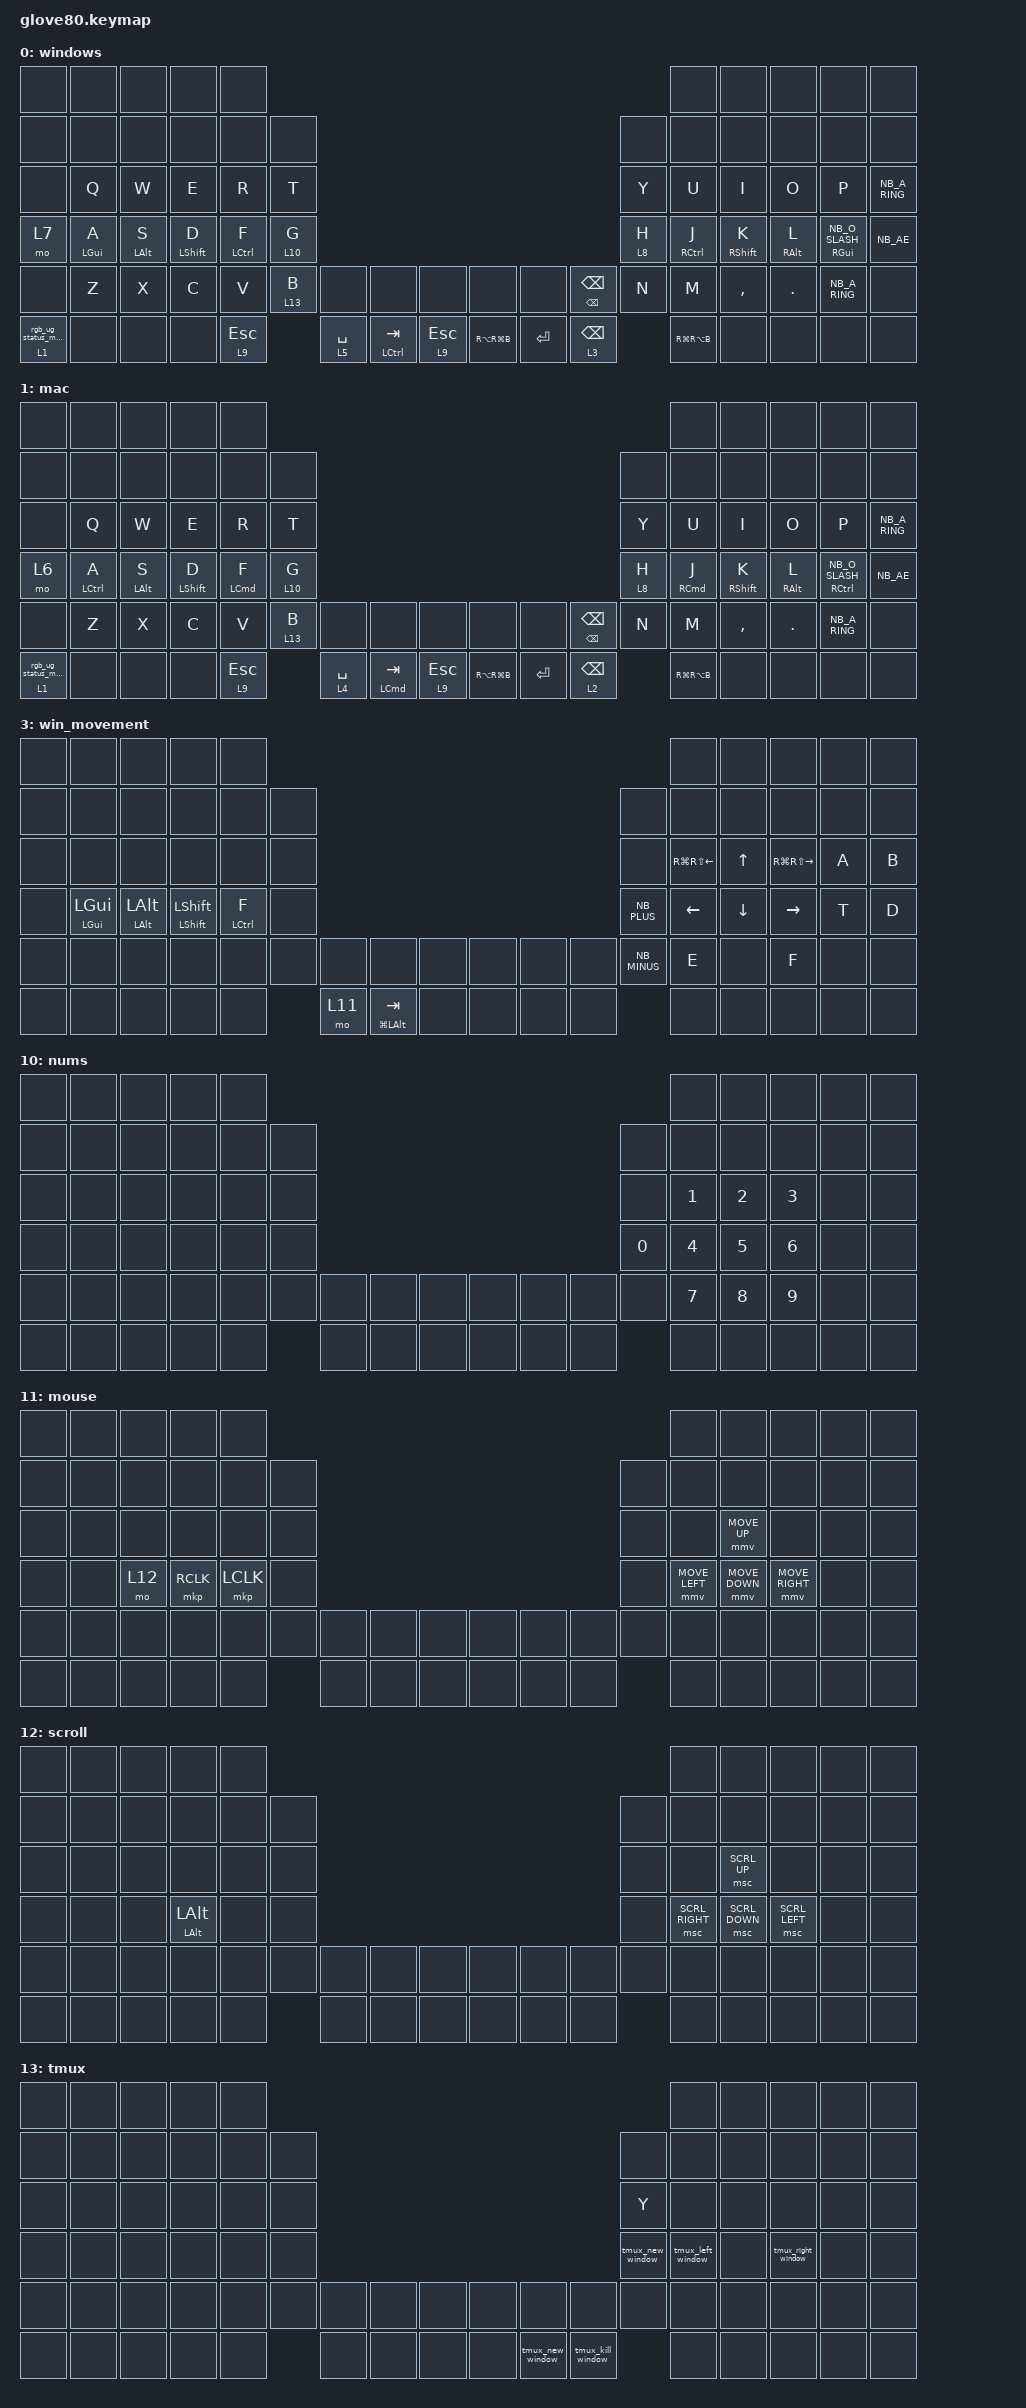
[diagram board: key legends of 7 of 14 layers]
/*
 * Copyright (c) 2020 The ZMK Contributors
 *
 * SPDX-License-Identifier: MIT
 */

#include "keys_nb.h"
#include <behaviors.dtsi>
#include <dt-bindings/zmk/bt.h>
#include <dt-bindings/zmk/keys.h>
#include <dt-bindings/zmk/outputs.h>
#include <dt-bindings/zmk/pointing.h>
#include <dt-bindings/zmk/rgb.h>

#define HYPER LC(LS(LG(LALT)))
#define ZMK_POINTING_DEFAULT_MOVE_VAL 900

// layers

#define DEFAULT 0
#define LOWER 1
#define MAGIC 2
#define FACTORY_TEST 3

/ {
    behaviors {
        // For the "layer" key, it'd nice to be able to use it as either a shift or a toggle.
        // Configure it as a tap dance, so the first tap (or hold) is a &mo and the second tap is a &to

        magic: magic_hold_tap {
            compatible = "zmk,behavior-hold-tap";
            label = "MAGIC_HOLD_TAP";
            #binding-cells = <2>;
            flavor = "tap-preferred";
            tapping-term-ms = <200>;
            bindings = <&mo>, <&rgb_ug_status_macro>;
        };

        mt: mod_tap {
            compatible = "zmk,behavior-hold-tap";
            bindings = <&kp>, <&kp>;

            #binding-cells = <2>;
            tapping-term-ms = <200>;
            require-prior-idle-ms = <150>;
            flavor = "tap-preferred";
            hold-trigger-on-release;
        };
    };

    macros {
        rgb_ug_status_macro: rgb_ug_status_macro_0 {
            label = "RGB_UG_STATUS";
            compatible = "zmk,behavior-macro";
            #binding-cells = <0>;
            bindings = <&rgb_ug RGB_STATUS>;
        };

        bt_0: bt_profile_macro_0 {
            label = "BT_0";
            compatible = "zmk,behavior-macro";
            #binding-cells = <0>;
            bindings = <&out OUT_BLE &bt BT_SEL 0>;
        };

        bt_1: bt_profile_macro_1 {
            label = "BT_1";
            compatible = "zmk,behavior-macro";
            #binding-cells = <0>;
            bindings = <&out OUT_BLE &bt BT_SEL 1>;
        };

        bt_2: bt_profile_macro_2 {
            label = "BT_2";
            compatible = "zmk,behavior-macro";
            #binding-cells = <0>;
            bindings = <&out OUT_BLE &bt BT_SEL 2>;
        };

        bt_3: bt_profile_macro_3 {
            label = "BT_3";
            compatible = "zmk,behavior-macro";
            #binding-cells = <0>;
            bindings = <&out OUT_BLE &bt BT_SEL 3>;
        };

        tmux_new_window: tmux_new_window {
            label = "TMUX_NEW_WINDOW";
            compatible = "zmk,behavior-macro";
            #binding-cells = <0>;
            bindings = <&kp RC(B) &kp C>;
        };

        tmux_kill_window: tmux_kill_window {
            label = "TMUX_KILL_WINDOW";
            compatible = "zmk,behavior-macro";
            #binding-cells = <0>;
            bindings = <&kp RC(B) &kp NB_AMPERSAND>;
        };

        tmux_left_window: tmux_left_arrow {
            label = "TMUX_LEFT_ARROW";
            compatible = "zmk,behavior-macro";
            #binding-cells = <0>;
            bindings = <&kp RC(B) &kp P>;
        };

        tmux_right_window: tmux_right_arrow {
            label = "TMUX_RIGHT_ARROW";
            compatible = "zmk,behavior-macro";
            #binding-cells = <0>;
            bindings = <&kp RC(B) &kp N>;
        };

        os_mac: os_mac {
            compatible = "zmk,behavior-macro";
            #binding-cells = <0>;
            bindings = <&bt BT_SEL 0 &to 1>;
            label = "OS_MAC";
        };

        os_win: os_win {
            compatible = "zmk,behavior-macro";
            #binding-cells = <0>;
            bindings = <&bt BT_SEL 1 &to 0>;
            label = "OS_WIN";
        };

        qurly_left: qurly_left {
            compatible = "zmk,behavior-macro";
            #binding-cells = <0>;
            bindings = <&kp RA(N7)>;
            label = "QURLY_LEFT";
        };

        os_mac2: os_mac2 {
            compatible = "zmk,behavior-macro";
            #binding-cells = <0>;
            bindings = <&bt BT_SEL 2 &to 1>;
            label = "OS_MAC2";
        };
    };

    keymap {
        compatible = "zmk,keymap";

        windows_base {
            label = "windows";
            bindings = <
&none       &none           &none           &none             &none                                                                                                                                 &none                &none              &none            &none                     &none
&none       &none           &none           &none             &none               &none                                                                                                    &none    &none                &none              &none            &none                     &none
&none       &kp Q           &kp W           &kp E             &kp R               &kp T                                                                                                    &kp Y    &kp U                &kp I              &kp O            &kp P                     &kp NB_A_RING
&mo 7       &mt LEFT_GUI A  &mt LEFT_ALT S  &mt LEFT_SHIFT D  &mt LEFT_CONTROL F  &lt 10 G                                                                                                 &lt 8 H  &mt RIGHT_CONTROL J  &mt RIGHT_SHIFT K  &mt RIGHT_ALT L  &mt RIGHT_GUI NB_O_SLASH  &kp NB_AE
&none       &kp Z           &kp X           &kp C             &kp V               &lt 13 B  &none        &none                 &none      &none          &none    &mt BACKSPACE BACKSPACE  &kp N    &kp M                &kp COMMA          &kp DOT          &kp NB_A_RING             &none
&magic 1 0  &none           &none           &none             &lt 9 ESC                     &lt 5 SPACE  &mt LEFT_CONTROL TAB  &lt 9 ESC  &kp RA(RG(B))  &kp RET  &lt 3 BACKSPACE                   &kp RG(RA(B))        &none              &none            &none                     &none
            >;
        };

        mac_base {
            // ---------------------------------------------------------------------------------------------------------------------------------
            // |  F1   |  F2 |  F3 |  F4  |  F5  |                                                               |  F6   |  F7   |  F8  |   F9  |  F10 |
            // |  =    |  1  |  2  |  3   |  4   |  5   |                                                 |  6   |   7   |   8   |  9   |   0   |   -  |
            // |  TAB  |  Q  |  W  |  E   |  R   |  T   |                                                 |  Y   |   U   |   I   |  O   |   P   |   \  |
            // |  ESC  |  A  |  S  |  D   |  F   |  G   |                                                 |  H   |   J   |   K   |  L   |   ;   |   '  |
            // |   `   |  Z  |  X  |  C   |  V   |  B   | LSHFT | LCTRL | LOWER | | LGUI  | RCTRL | RSHFT |  N   |   M   |   ,   |  .   |   /   | PGUP |
            // | MAGIC | HOME| END | LEFT | RIGHT|      | BSPC  | DEL   | LALT  | | RALT  | RET   | SPACE |      |  UP   | DOWN  |  [   |   ]   | PGDN |

            bindings = <
&none       &none               &none           &none             &none                                                                                                                                 &none                &none              &none            &none                         &none
&none       &none               &none           &none             &none               &none                                                                                                    &none    &none                &none              &none            &none                         &none
&none       &kp Q               &kp W           &kp E             &kp R               &kp T                                                                                                    &kp Y    &kp U                &kp I              &kp O            &kp P                         &kp NB_A_RING
&mo 6       &mt LEFT_CONTROL A  &mt LEFT_ALT S  &mt LEFT_SHIFT D  &mt LEFT_COMMAND F  &lt 10 G                                                                                                 &lt 8 H  &mt RIGHT_COMMAND J  &mt RIGHT_SHIFT K  &mt RIGHT_ALT L  &mt RIGHT_CONTROL NB_O_SLASH  &kp NB_AE
&none       &kp Z               &kp X           &kp C             &kp V               &lt 13 B  &none        &none                 &none      &none          &none    &mt BACKSPACE BACKSPACE  &kp N    &kp M                &kp COMMA          &kp DOT          &kp NB_A_RING                 &none
&magic 1 0  &none               &none           &none             &lt 9 ESC                     &lt 4 SPACE  &mt LEFT_COMMAND TAB  &lt 9 ESC  &kp RA(RG(B))  &kp RET  &lt 2 BACKSPACE                   &kp RG(RA(B))        &none              &none            &none                         &none
            >;

            label = "mac";
        };

        Mac_Movement {
            bindings = <
&none  &none                          &none                  &none                      &none                                                                                                                                          &none           &none           &none            &none  &none
&none  &none                          &none                  &none                      &none                          &none                                                                                             &none         &none           &none           &none            &none  &none
&none  &none                          &none                  &none                      &none                          &none                                                                                             &none         &kp HOME        &kp UP_ARROW    &kp END          &kp A  &kp B
&none  &mt LEFT_CONTROL LEFT_CONTROL  &mt LEFT_ALT LEFT_ALT  &mt LEFT_SHIFT LEFT_SHIFT  &mt LEFT_COMMAND LEFT_COMMAND  &none                                                                                             &kp NB_PLUS   &kp LEFT_ARROW  &kp DOWN_ARROW  &kp RIGHT_ARROW  &kp T  &kp D
&none  &none                          &none                  &none                      &none                          &none  &kp LS(LC(LG(LEFT_ALT)))  &none                     &none             &none  &none  &none  &kp NB_MINUS  &kp E           &none           &kp F            &none  &none
&none  &none                          &none                  &none                      &none                                 &mo 11                    &kp LG(LC(LS(LEFT_ALT)))  &kp LEFT_CONTROL  &none  &none  &none                &none           &none           &none            &none  &none
            >;

            label = "mac_movement";
        };

        Windows_Movement {
            label = "win_movement";
            bindings = <
&none  &none                  &none                  &none                      &none                                                                                              &none                   &none           &none                    &none  &none
&none  &none                  &none                  &none                      &none               &none                                                            &none         &none                   &none           &none                    &none  &none
&none  &none                  &none                  &none                      &none               &none                                                            &none         &kp RG(RS(LEFT_ARROW))  &kp UP_ARROW    &kp RG(RS(RIGHT_ARROW))  &kp A  &kp B
&none  &mt LEFT_GUI LEFT_GUI  &mt LEFT_ALT LEFT_ALT  &mt LEFT_SHIFT LEFT_SHIFT  &mt LEFT_CONTROL F  &none                                                            &kp NB_PLUS   &kp LEFT_ARROW          &kp DOWN_ARROW  &kp RIGHT_ARROW          &kp T  &kp D
&none  &none                  &none                  &none                      &none               &none  &none   &none                 &none  &none  &none  &none  &kp NB_MINUS  &kp E                   &none           &kp F                    &none  &none
&none  &none                  &none                  &none                      &none                      &mo 11  &mt LG(LEFT_ALT) TAB  &none  &none  &none  &none                &none                   &none           &none                    &none  &none
            >;
        };

        mac_symbols {
            bindings = <
&none  &none                                  &none                    &none                &none                                                                                                      &none                    &none                     &none         &none                 &none
&none  &none                                  &none                    &none                &none              &none                                                               &none               &none                    &none                     &none         &none                 &none
&none  &kp LS(NUMBER_4)                       &kp NB_LESS_THAN         &kp NB_GREATER_THAN  &kp NB_UNDERSCORE  &kp LA(N7)                                                          &kp NB_AMPERSAND    &kp RS(RA(NB_N8))        &kp RS(RA(NB_N9))         &kp NB_EQUAL  &kp RA(SINGLE_QUOTE)  &none
&none  &kp NB_DOUBLE_QUOTES                   &kp LA(NB_SINGLE_QUOTE)  &kp NB_SEMICOLON     &kp NB_COLON       &kp NB_SLASH                                                        &kp NB_QUESTION     &kp NB_LEFT_PARENTHESIS  &kp NB_RIGHT_PARENTHESIS  &kp NB_PLUS   &kp NB_SQT            &none
&none  &mt LA(LC(LG(LEFT_SHIFT))) LEFT_SHIFT  &none                    &none                &kp NB_HASH        &kp NB_ASTERISK  &none  &none  &none  &none  &none           &none  &kp NB_EXCLAMATION  &kp NB_LEFT_BRACKET      &kp NB_RIGHT_BRACKET      &kp NB_MINUS  &none                 &none
&none  &none                                  &none                    &none                &none                               &none  &none  &none  &none  &kp NB_PERCENT  &none                      &none                    &none                     &none         &none                 &none
            >;

            label = "m_symbols";
        };

        win_symbols {
            label = "w_symbols";
            bindings = <
&none  &none                                  &none             &none                &none                                                                                                      &none                    &none                              &none         &none            &none
&none  &none                                  &none             &none                &none              &none                                                               &none               &none                    &none                              &none         &none            &none
&none  &kp DLLR                               &kp NB_LESS_THAN  &kp NB_GREATER_THAN  &kp NB_UNDERSCORE  &kp NB_PIPE                                                         &kp NB_AMPERSAND    &kp NB_LEFT_BRACE        &mt NB_RIGHT_BRACE NB_RIGHT_BRACE  &kp NB_EQUAL  &kp NB_EQUAL     &none
&none  &kp NB_DOUBLE_QUOTES                   &kp NB_SQT        &kp NB_SEMICOLON     &kp NB_COLON       &kp NB_SLASH                                                        &kp NB_QUESTION     &kp NB_LEFT_PARENTHESIS  &kp NB_RIGHT_PARENTHESIS           &kp NB_PLUS   &mt NB_AT NB_AT  &none
&none  &mt LA(LC(LG(LEFT_SHIFT))) LEFT_SHIFT  &kp NB_BACKSLASH  &none                &kp NB_HASH        &kp NB_ASTERISK  &none  &none  &none  &none  &none           &none  &kp NB_EXCLAMATION  &kp RC(RA(N8))           &kp RC(RA(N9))                     &kp NB_MINUS  &none            &none
&none  &none                                  &none             &none                &none                               &none  &none  &none  &none  &kp NB_PERCENT  &none                      &none                    &none                              &none         &none            &none
            >;
        };

        Misc_mac {
            bindings = <
&none  &none  &none       &none                 &none                                                                                                &none              &none            &none       &none       &none
&none  &none  &none       &none                 &none                 &none                                                        &none             &none              &none            &none       &none       &none
&none  &none  &bt BT_CLR  &none                 &os_mac               &os_win                                                      &kp C_PLAY_PAUSE  &kp C_VOLUME_DOWN  &kp C_VOLUME_UP  &kp C_PREV  &kp C_NEXT  &none
&none  &none  &none       &kp LS(LG(NUMBER_5))  &kp LS(LG(NUMBER_4))  &kp LS(LA(S))                                                &none             &none              &none            &none       &none       &none
&none  &none  &none       &none                 &none                 &kp LS(LA(LC(S)))  &none  &none  &none  &none  &none  &none  &none             &none              &none            &none       &none       &none
&none  &none  &none       &none                 &none                                    &none  &none  &none  &none  &none  &none                    &none              &none            &none       &none       &none
            >;

            label = "misc_mac";
        };

        misc_win {
            label = "misc_win";
            bindings = <
&none  &none  &none       &none                 &none                                                                                         &none              &none            &none       &none       &none
&none  &none  &none       &none                 &none          &none                                                        &none             &none              &none            &none       &none       &none
&none  &none  &bt BT_CLR  &none                 &os_mac        &os_win                                                      &kp C_PLAY_PAUSE  &kp C_VOLUME_DOWN  &kp C_VOLUME_UP  &kp C_PREV  &kp C_NEXT  &none
&none  &none  &none       &kp LS(LG(NUMBER_5))  &kp LS(LG(S))  &kp LS(LA(S))                                                &none             &kp RA(RS(N5))     &none            &none       &none       &none
&none  &none  &none       &none                 &none          &kp LS(LA(LC(S)))  &none  &none  &none  &none  &none  &none  &none             &none              &none            &none       &none       &none
&none  &none  &none       &none                 &none                             &none  &none  &none  &none  &none  &none                    &none              &none            &none       &none       &none
            >;
        };

        Apps {
            bindings = <
&none                   &none       &none           &none       &none                                                                          &none  &none  &none  &none  &none
&none                   &none       &none           &none       &none       &none                                                       &none  &none  &none  &none  &none  &none
&kp LS(LA(LC(LG(N1))))  &kp LC(N8)  &kp LC(N1)      &kp LC(N2)  &kp LC(N3)  &kp LC(NUMBER_0)                                            &none  &none  &none  &none  &none  &none
&none                   &kp LC(N9)  &kp LS(LC(N7))  &kp LC(N7)  &kp LC(N6)  &kp LS(LC(N6))                                              &none  &none  &none  &none  &none  &none
&none                   &none       &none           &none       &none       &kp LG(Q)         &none  &none  &none  &none  &none  &none  &none  &none  &none  &none  &none  &none
&none                   &none       &none           &none       &none                         &none  &none  &none  &none  &none  &none         &none  &none  &none  &none  &none
            >;

            label = "apps";
        };

        IDE {
            bindings = <
&none  &none  &none  &none  &none                                                                                &none                         &none             &none                         &none  &none
&none  &none  &none  &none  &none  &none                                                              &none      &none                         &none             &none                         &none  &none
&none  &none  &none  &none  &none  &none                                                              &kp RG(W)  &kp RG(NUMBER_1)              &kp RG(NUMBER_2)  &kp RG(NUMBER_3)              &none  &none
&none  &none  &none  &none  &none  &none                                                              &kp RG(P)  &kp RG(RC(RA(RS(NUMBER_5))))  &none             &kp RS(RA(RC(RG(NUMBER_6))))  &none  &none
&none  &none  &none  &none  &none  &none  &none  &none  &none  &none  &none            &none          &none      &none                         &none             &none                         &none  &none
&none  &none  &none  &none  &none         &none  &none  &none  &none  &kp RC(NB_PLUS)  &kp RG(RS(E))             &none                         &none             &none                         &none  &none
            >;

            label = "ide";
        };

        Nums {
            bindings = <
&none  &none  &none  &none  &none                                                           &none         &none   &none   &none  &none
&none  &none  &none  &none  &none  &none                                            &none   &none         &none   &none   &none  &none
&none  &none  &none  &none  &none  &none                                            &none   &kp N1        &kp N2  &kp N3  &none  &none
&none  &none  &none  &none  &none  &none                                            &kp N0  &kp NUMBER_4  &kp N5  &kp N6  &none  &none
&none  &none  &none  &none  &none  &none  &none  &none  &none  &none  &none  &none  &none   &kp N7        &kp N8  &kp N9  &none  &none
&none  &none  &none  &none  &none         &none  &none  &none  &none  &none  &none          &none         &none   &none   &none  &none
            >;

            label = "nums";
        };

        Mouse {
            bindings = <
&none  &none  &none   &none      &none                                                              &none           &none           &none            &none  &none
&none  &none  &none   &none      &none      &none                                            &none  &none           &none           &none            &none  &none
&none  &none  &none   &none      &none      &none                                            &none  &none           &mmv MOVE_UP    &none            &none  &none
&none  &none  &mo 12  &mkp RCLK  &mkp LCLK  &none                                            &none  &mmv MOVE_LEFT  &mmv MOVE_DOWN  &mmv MOVE_RIGHT  &none  &none
&none  &none  &none   &none      &none      &none  &none  &none  &none  &none  &none  &none  &none  &none           &none           &none            &none  &none
&none  &none  &none   &none      &none             &none  &none  &none  &none  &none  &none         &none           &none           &none            &none  &none
            >;

            label = "mouse";
        };

        Scroll {
            bindings = <
&none  &none  &none  &none                  &none                                                          &none            &none           &none           &none  &none
&none  &none  &none  &none                  &none  &none                                            &none  &none            &none           &none           &none  &none
&none  &none  &none  &none                  &none  &none                                            &none  &none            &msc SCRL_UP    &none           &none  &none
&none  &none  &none  &mt LEFT_ALT LEFT_ALT  &none  &none                                            &none  &msc SCRL_RIGHT  &msc SCRL_DOWN  &msc SCRL_LEFT  &none  &none
&none  &none  &none  &none                  &none  &none  &none  &none  &none  &none  &none  &none  &none  &none            &none           &none           &none  &none
&none  &none  &none  &none                  &none         &none  &none  &none  &none  &none  &none         &none            &none           &none           &none  &none
            >;

            label = "scroll";
        };

        Tmux {
            bindings = <
&none  &none  &none  &none  &none                                                                                            &none              &none  &none               &none  &none
&none  &none  &none  &none  &none  &none                                                                   &none             &none              &none  &none               &none  &none
&none  &none  &none  &none  &none  &none                                                                   &kp Y             &none              &none  &none               &none  &none
&none  &none  &none  &none  &none  &none                                                                   &tmux_new_window  &tmux_left_window  &none  &tmux_right_window  &none  &none
&none  &none  &none  &none  &none  &none  &none  &none  &none  &none  &none             &none              &none             &none              &none  &none               &none  &none
&none  &none  &none  &none  &none         &none  &none  &none  &none  &tmux_new_window  &tmux_kill_window                    &none              &none  &none               &none  &none
            >;

            label = "tmux";
        };
    };
};
